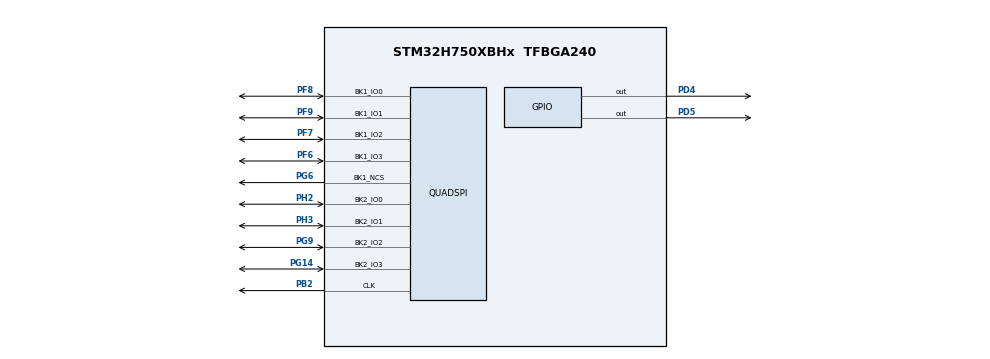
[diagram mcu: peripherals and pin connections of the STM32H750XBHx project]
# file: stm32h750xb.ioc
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CORTEX_M7.MPU_Control=__NULL
CORTEX_M7.default_mode_Activation=1
Mcu.Family=STM32H7
Mcu.Name=STM32H750XBHx
Mcu.Package=TFBGA240
NVIC.PriorityGroup=NVIC_PRIORITYGROUP_4
PB2.GPIO_Speed=GPIO_SPEED_FREQ_VERY_HIGH
PB2.Mode=Dual_Bank
PB2.Signal=QUADSPI_CLK
PC14-OSC32_IN\ (OSC32_IN).Mode=LSE-External-Oscillator
PC14-OSC32_IN\ (OSC32_IN).Signal=RCC_OSC32_IN
PC15-OSC32_OUT\ (OSC32_OUT).Mode=LSE-External-Oscillator
PC15-OSC32_OUT\ (OSC32_OUT).Signal=RCC_OSC32_OUT
PD4.PinState=GPIO_PIN_SET
PD4.Signal=GPIO_Output
PD5.PinState=GPIO_PIN_SET
PD5.Signal=GPIO_Output
PF6.GPIO_Speed=GPIO_SPEED_FREQ_VERY_HIGH
PF6.Mode=Dual_Bank
PF6.Signal=QUADSPI_BK1_IO3
PF7.GPIO_Speed=GPIO_SPEED_FREQ_VERY_HIGH
PF7.Mode=Dual_Bank
PF7.Signal=QUADSPI_BK1_IO2
PF8.GPIO_Speed=GPIO_SPEED_FREQ_VERY_HIGH
PF8.Mode=Dual_Bank
PF8.Signal=QUADSPI_BK1_IO0
PF9.GPIO_Speed=GPIO_SPEED_FREQ_VERY_HIGH
PF9.Mode=Dual_Bank
PF9.Signal=QUADSPI_BK1_IO1
PG14.GPIO_Speed=GPIO_SPEED_FREQ_VERY_HIGH
PG14.Mode=Dual_Bank
PG14.Signal=QUADSPI_BK2_IO3
PG6.GPIO_Speed=GPIO_SPEED_FREQ_VERY_HIGH
PG6.Mode=Enable Chip Select 1 for both banks
PG6.Signal=QUADSPI_BK1_NCS
PG9.GPIO_Speed=GPIO_SPEED_FREQ_VERY_HIGH
PG9.Mode=Dual_Bank
PG9.Signal=QUADSPI_BK2_IO2
PH0-OSC_IN\ (PH0).Mode=HSE-External-Oscillator
PH0-OSC_IN\ (PH0).Signal=RCC_OSC_IN
PH1-OSC_OUT\ (PH1).Mode=HSE-External-Oscillator
PH1-OSC_OUT\ (PH1).Signal=RCC_OSC_OUT
PH2.GPIO_Speed=GPIO_SPEED_FREQ_VERY_HIGH
PH2.Mode=Dual_Bank
PH2.Signal=QUADSPI_BK2_IO0
PH3.GPIO_Speed=GPIO_SPEED_FREQ_VERY_HIGH
PH3.Mode=Dual_Bank
PH3.Signal=QUADSPI_BK2_IO1
ProjectManager.HeapSize=0x200
ProjectManager.StackSize=0x400
ProjectManager.TargetToolchain=STM32CubeIDE
QUADSPI.ChipSelectHighTime=QSPI_CS_HIGH_TIME_8_CYCLE
QUADSPI.ClockPrescaler=3
QUADSPI.FifoThreshold=32
QUADSPI.FlashSize=27
QUADSPI.SampleShifting=QSPI_SAMPLE_SHIFTING_NONE
RCC.ADCFreq_Value=480000000
RCC.APB1Freq_Value=120000000
RCC.APB2Freq_Value=120000000
RCC.APB3Freq_Value=120000000
RCC.APB4Freq_Value=120000000
RCC.CortexFreq_Value=480000000
RCC.D1PPRE=RCC_APB3_DIV2
RCC.D2PPRE1=RCC_APB1_DIV2
RCC.D2PPRE2=RCC_APB2_DIV2
RCC.D3PPRE=RCC_APB4_DIV2
RCC.DIVM1=5
RCC.DIVM2=5
RCC.DIVN1=192
RCC.DIVN2=192
RCC.HCLKFreq_Value=240000000
RCC.HPRE=RCC_HCLK_DIV2
RCC.PLLSourceVirtual=RCC_PLLSOURCE_HSE
RCC.ProductRev=revV
RCC.SYSCLKFreq_VALUE=480000000
RCC.SYSCLKSource=RCC_SYSCLKSOURCE_PLLCLK
RCC.USBFreq_Value=480000000
board=custom

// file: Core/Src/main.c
/* USER CODE BEGIN Header */
/**
  ******************************************************************************
  * @file           : main.c
  * @brief          : Main program body
  ******************************************************************************
  * @attention
  *
  * Copyright (c) 2024 STMicroelectronics.
  * All rights reserved.
  *
  * This software is licensed under terms that can be found in the LICENSE file
  * in the root directory of this software component.
  * If no LICENSE file comes with this software, it is provided AS-IS.
  *
  ******************************************************************************
  */
/* USER CODE END Header */
#include "main.h"
#include "quadspi.h"
#include "gpio.h"

void SystemClock_Config(void);
/* USER CODE BEGIN PFP */
extern int Init(void);
/* USER CODE END PFP */

/* USER CODE BEGIN 0 */
HAL_StatusTypeDef HAL_InitTick(uint32_t TickPriority)
{
    return HAL_OK;
}

void HAL_Delay(uint32_t Delay)
{
    volatile int i=0;
    for (i=0; i<0x1000; i++);
}

uint32_t HAL_GetTick(void)
{
    volatile int i;
    for (i=0; i < 512; i++);
    uwTick++;
    return uwTick;
}
/* USER CODE END 0 */

void SystemClock_Config(void)
{
  RCC_OscInitTypeDef RCC_OscInitStruct = {0};
  RCC_ClkInitTypeDef RCC_ClkInitStruct = {0};

  /** Supply configuration update enable
  */
  HAL_PWREx_ConfigSupply(PWR_LDO_SUPPLY);

  /** Configure the main internal regulator output voltage
  */
  __HAL_PWR_VOLTAGESCALING_CONFIG(PWR_REGULATOR_VOLTAGE_SCALE1);

  while(!__HAL_PWR_GET_FLAG(PWR_FLAG_VOSRDY)) {}

  __HAL_RCC_SYSCFG_CLK_ENABLE();
  __HAL_PWR_VOLTAGESCALING_CONFIG(PWR_REGULATOR_VOLTAGE_SCALE0);

  while(!__HAL_PWR_GET_FLAG(PWR_FLAG_VOSRDY)) {}

  /** Initializes the RCC Oscillators according to the specified parameters
  * in the RCC_OscInitTypeDef structure.
  */
  RCC_OscInitStruct.OscillatorType = RCC_OSCILLATORTYPE_HSE;
  RCC_OscInitStruct.HSEState = RCC_HSE_ON;
  RCC_OscInitStruct.PLL.PLLState = RCC_PLL_ON;
  RCC_OscInitStruct.PLL.PLLSource = RCC_PLLSOURCE_HSE;
  RCC_OscInitStruct.PLL.PLLM = 5;
  RCC_OscInitStruct.PLL.PLLN = 192;
  RCC_OscInitStruct.PLL.PLLP = 2;
  RCC_OscInitStruct.PLL.PLLQ = 2;
  RCC_OscInitStruct.PLL.PLLR = 2;
  RCC_OscInitStruct.PLL.PLLRGE = RCC_PLL1VCIRANGE_2;
  RCC_OscInitStruct.PLL.PLLVCOSEL = RCC_PLL1VCOWIDE;
  RCC_OscInitStruct.PLL.PLLFRACN = 0;
  if (HAL_RCC_OscConfig(&RCC_OscInitStruct) != HAL_OK)
  {
    Error_Handler();
  }

  /** Initializes the CPU, AHB and APB buses clocks
  */
  RCC_ClkInitStruct.ClockType = RCC_CLOCKTYPE_HCLK|RCC_CLOCKTYPE_SYSCLK
                              |RCC_CLOCKTYPE_PCLK1|RCC_CLOCKTYPE_PCLK2
                              |RCC_CLOCKTYPE_D3PCLK1|RCC_CLOCKTYPE_D1PCLK1;
  RCC_ClkInitStruct.SYSCLKSource = RCC_SYSCLKSOURCE_PLLCLK;
  RCC_ClkInitStruct.SYSCLKDivider = RCC_SYSCLK_DIV1;
  RCC_ClkInitStruct.AHBCLKDivider = RCC_HCLK_DIV2;
  RCC_ClkInitStruct.APB3CLKDivider = RCC_APB3_DIV2;
  RCC_ClkInitStruct.APB1CLKDivider = RCC_APB1_DIV2;
  RCC_ClkInitStruct.APB2CLKDivider = RCC_APB2_DIV2;
  RCC_ClkInitStruct.APB4CLKDivider = RCC_APB4_DIV2;

  if (HAL_RCC_ClockConfig(&RCC_ClkInitStruct, FLASH_LATENCY_4) != HAL_OK)
  {
    Error_Handler();
  }
}

void Error_Handler(void)
{
    __disable_irq();
    while (1)
    {
    }
}
